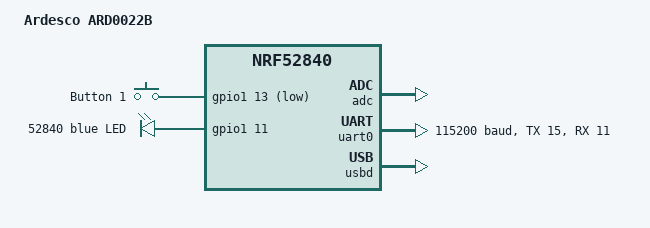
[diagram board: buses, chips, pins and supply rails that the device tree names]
/*
 * Copyright (c) 2019 Nordic Semiconductor ASA
 * Copyright (c) Ericsson AB 2020, all rights reserved
 *
 * SPDX-License-Identifier: LicenseRef-BSD-5-Clause-Nordic
 */

/dts-v1/;
#include <nordic/nrf52840_qiaa.dtsi>

/ {
	model = "Ardesco ARD0022B";
	compatible = "nordic,pca20035";

	chosen {
		zephyr,console = &uart0;
		zephyr,flash = &flash0;
		zephyr,sram = &sram0;
		zephyr,uart-mcumgr = &uart0;
	};

	buttons {
		compatible = "gpio-keys";

		/* Boot button for 52840 */
		button0: button_0 {
			gpios = <&gpio1 13 (GPIO_PULL_UP | GPIO_ACTIVE_LOW)>;
			label = "Button 1";
		};
	};

	leds {
		compatible = "gpio-leds";
		led0: led_0 {
			gpios = <&gpio1 11 0>;
			label = "52840 blue LED";
		};
	};

	/* These aliases are provided for compatibility with samples */
	aliases {
		btn0 = &button0;
		led0 = &led0;
	};
};

&adc {
	status = "okay";
};

&gpiote {
	status = "okay";
};

&gpio0 {
	status = "okay";
};

&gpio1 {
	status = "okay";
};

&uart0 {
	compatible = "nordic,nrf-uarte";
	current-speed = <115200>;
	status = "okay";
	tx-pin = <15>;
	rx-pin = <11>;
	rts-pin = <21>;
	cts-pin = <20>;
};

&usbd {
	status = "okay";
};

&flash0 {
	partitions {
		compatible = "fixed-partitions";
		#address-cells = <1>;
		#size-cells = <1>;

		/* The size of this partition ensures that MCUBoot can be built
		 * with an RTT console, CDC ACM support, and w/o optimizations.
		 */
		boot_partition: partition@0 {
			label = "mcuboot";
			reg = <0x000000000 0x00012000>;
		};
		slot0_partition: partition@12000 {
			label = "image-0";
			reg = <0x00012000 0x000069000>;
		};
		slot1_partition: partition@7b000 {
			label = "image-1";
			reg = <0x0007b000 0x000069000>;
		};
		scratch_partition: partition@e4000 {
			label = "image-scratch";
			reg = <0x000e4000 0x00018000>;
		};
		storage_partition: partition@fc000 {
			label = "storage";
			reg = <0x000fc000 0x00004000>;
		};
	};
};
